# WE2_S_NS register map
Vendor: ARM Ltd.; Series: ARMv8.1-M Mainline; File version: 1.0
CPU: CM55 r1p1, little endian, MPU, FPU, double-precision FPU, DSP, VTOR, 3 interrupt priority bits
Registers are 32-bit, read-write, reset 0x0 unless marked. A register's access mark holds for its fields unless they carry their own. Offsets are from the block's base; [hi:lo] are bit positions; {n}, {i} and the like mark numbered series; 'fields as' and 'values as' point back to an identical list.

## SYS_IMPL_DEF
Base 0xE001E000
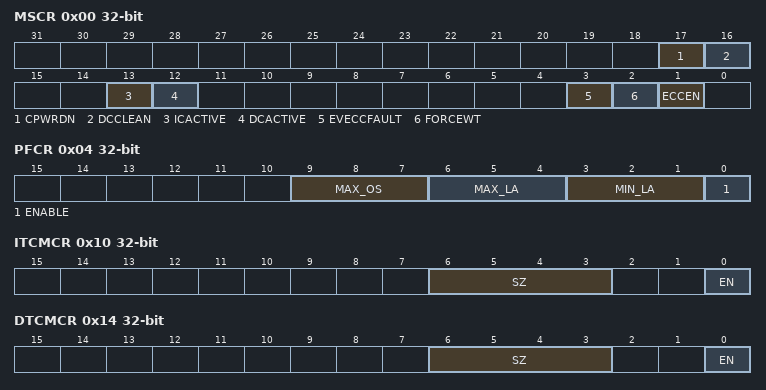
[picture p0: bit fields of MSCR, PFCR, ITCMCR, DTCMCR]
0x00 MSCR — Memory System Control
  [17] CPWRDN
  [16] DCCLEAN — This bit indicates whether the data cache contains any dirty lines
  [13] ICACTIVE — This bit indicates whether the L1 instruction cache is active
  [12] DCACTIVE — This bit indicates whether the L1 data cache is active
  [3] EVECCFAULT — Enables asynchronous BusFault exceptions when data is lost on evictions
  [2] FORCEWT — Enables Forced Write-Through in the L1 data cach
  [1] ECCEN ro — Indicates whether Error Correcting Code (ECC) is present and enabled.
0x04 PFCR — Prefetcher Control Register
  [9:7] MAX_OS — Maximum outstanding line-fills
  [6:4] MAX_LA — Maximum look-ahead distance
  [3:1] MIN_LA — Minimum look-ahead distance
  [0] ENABLE — Prefetcher enable
0x10 ITCMCR — The ITCMCR registers enable access to the Tightly Coupled Memories (TCMs)
  [6:3] SZ ro — TCM size indicates the size of the relevant TCM
  [0] EN — TCM enable
0x14 DTCMCR — The DTCMCR registers enable access to the Tightly Coupled Memories (TCMs)
  fields as ITCMCR
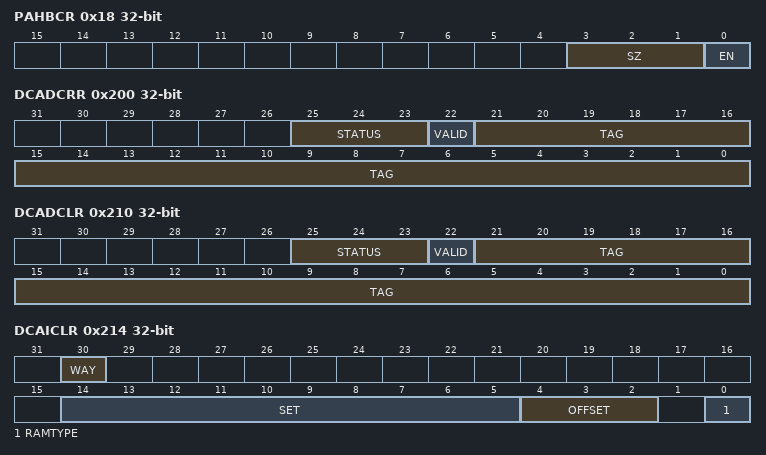
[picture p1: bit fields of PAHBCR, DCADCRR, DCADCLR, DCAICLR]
0x18 PAHBCR — P-AHB Control Register
  [3:1] SZ ro — P-AHB size
  [0] EN — P-AHB enable
0xB4 EVENTMASK12 ro — Wake-up Event Mask Registers
  [31:0] IRQ — Masks for interrupts ((n-1)x32) to (nx32)-1. For EVENTMASKn.IRQ[m] fields, any interrupt that the WIC does not support is RAZ.
0x100 IEBR0 — Instruction Cache Error Bank Register 0
0x104 IEBR1 — Instruction Cache Error Bank Register 1
0x110 DEBR0 — Data Cache Error Bank Register 0
0x114 DEBR1 — Data Cache Error Bank Register 0
0x120 TEBR0 — TCM Error Bank Register 0
0x124 TEBRDATA0 ro — Data for TCU Error Bank Register 0
0x128 TEBR1 — TCM Error Bank Register 1
0x12C TEBRDATA1 ro — Data for TCU Error Bank Register 1
0x200 DCADCRR ro — Direct Cache Access Read Registers
  [25:23] STATUS — Clean or dirty, transient, and outer attributes of the cache line
  [22] VALID — Valid state of the data cache line entry.
  [21:0] TAG — Tag address. The number of significant bits of TAG depends on the data cache size. Bits [21:N] 64KB N=4 32KB N=3 16KB N=2 8KB N=1 4KB N=0
0x210 DCADCLR ro — Direct Cache Access Location Registers
  fields as DCADCRR
0x214 DCAICLR ro — Direct Cache Access Location Registers
  [30] WAY — Cache way
  [14:5] SET — Set index. The value of N depends on the cache size. Bits [N:5] The options are: 64KB N=14 32KB N=13 16KB N=12 8KB N=11 4KB N=10
  [4:2] OFFSET
  [0] RAMTYPE — RAM type [0] Tag RAM [1] Data RAM
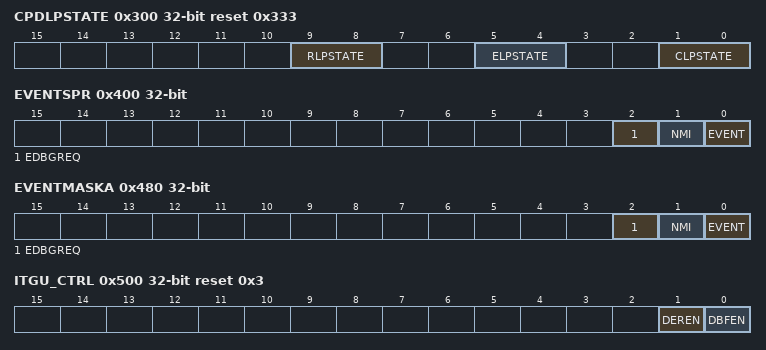
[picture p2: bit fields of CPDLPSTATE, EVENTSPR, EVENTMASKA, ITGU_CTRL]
0x300 CPDLPSTATE reset 0x333 — Core Power Domain Low Power State Register
  [9:8] RLPSTATE — Power-on state for PDRAMS power domain. [0b00] ON. [0b01] Reserved. [0b10] Reserved. [0b11] OFF. If the Level 1 (L1) data cache and instruction cache is not present, this field is RAZ/WI. The reset value is 0b11 on Cold reset.
  [5:4] ELPSTATE — Type of low-power state for PDEPU. [0b00] ON. PDEPU is not in low-power state. [0b01] ON, but the clock is off. [0b10] RET. [0b11] OFF. If the Extension Processing Unit (EPU) is not present, this field is RAZ/WI. The reset value is 0b11 on Cold reset.
  [1:0] CLPSTATE — Type of low-power state for PDCORE. [0b00] ON. PDCORE is not in low-power state. [0b01] ON, but the clock is off. [0b10] RET. [0b11] OFF. The reset value is 0b11 on Cold reset.
0x304 DPDLPSTATE reset 0x3 — Debug Power Domain Low Power State Register
  [1:0] DLPSTATE — Type of low-power state for PDDEBUG. [0b00] ON. PDDEBUG is not in low-power state. [0b01] ON, but the clock is off. [0b10] RESERVED. Treated as ON, but clock OFF. [0b11] OFF. The reset value is 0b11 at debug Cold reset
0x400 EVENTSPR wo — Event Set Pending Register
  [2] EDBGREQ — A write of one to this field causes the processor to behave like an external debug request has occurred. A write of zero is ignored.
  [1] NMI — A write of one to this field causes the processor to behave like a Non-maskable Interrupt (NMI) has occurred. A write of zero is ignored.
  [0] EVENT — A write of one to this field causes the processor to behave like an RXEV event has occurred. A write of zero is ignored.
0x480 EVENTMASKA ro — Wake-up Event Mask Registers
  [2] EDBGREQ — Mask for external debug request
  [1] NMI — Mask for Non-Maskable Interrupt (NMI)
  [0] EVENT — Sensitive to RXEV when in WFE sleep
{0x484+4i} EVENTMASK{i} ro (i=0..2) — Wake-up Event Mask Registers
  fields as EVENTMASK12
0x490 EVENTMASK3 — Wake-up Event Mask Registers
{0x484+4i} EVENTMASK{i} ro (i=4..11) — Wake-up Event Mask Registers
  fields as EVENTMASK12
{0x484+4i} EVENTMASK{i} ro (i=13..15) — Wake-up Event Mask Registers
  fields as EVENTMASK12
0x500 ITGU_CTRL reset 0x3 — ITGU Control Register
  [1] DEREN — Enable Slave AHB (S-AHB) error response for TGU fault. The options are: [0] Error response not enabled. [1] Error response enabled.
  [0] DBFEN — Enable data side BusFault for TGU fault. The options are: [0] BusFault not enabled. [1] BusFault enabled.
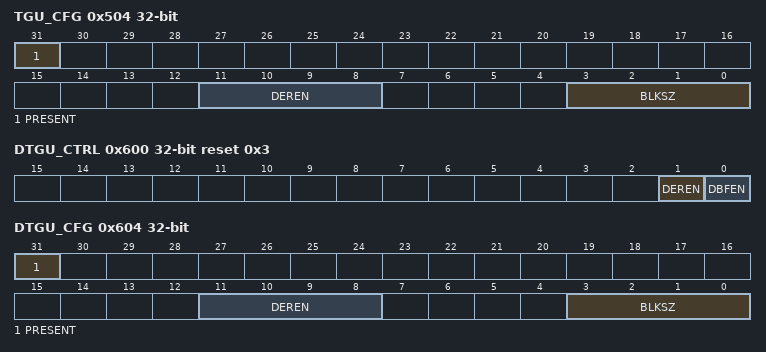
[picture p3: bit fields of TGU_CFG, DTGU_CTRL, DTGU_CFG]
0x504 TGU_CFG ro — ITGU Configuration Registers
  [31] PRESENT — This field determines if the TGU is present. The options are: [0] TGU not present. [1] TGU is present.
  [11:8] DEREN — This value is used to calculate the number of TCM blocks The value is 2NUMBLKS . The value of NUMBLKS is: NUMBLKS=(CFGxTCMSZ+4)-xTGUBLKSZ. Where: - NUMBLKS is the number of TCM blocks. - CFGxTCMSZ is the configured TCM size. - xTGUBLKSZ is the configured Instruction Tightly Coupled Memory Gate Unit (ITGU) or Data Tightly Coupled Memory Gate Unit (DTGU) block size.
  [3:0] BLKSZ — TGU block size in bytes. This is 2BLKSZ+5 . This field is determined by the Verilog parameter xTGUBLKSZ.
{0x510+4i} ITGU_LUT{i} (i=0..15) — ITGU Look Up Table Registers
0x600 DTGU_CTRL reset 0x3 — DTGU Control Register
  fields as ITGU_CTRL
0x604 DTGU_CFG ro — DTGU Configuration Registers
  fields as TGU_CFG
{0x610+4i} DTGU_LUT{i} (i=0..15) — DTGU Look Up Table Registers
0x700 CFGINFOSEL wo — Processor configuration information selection register
0x704 CFGINFORD ro — Processor Processor configuration information read data register
